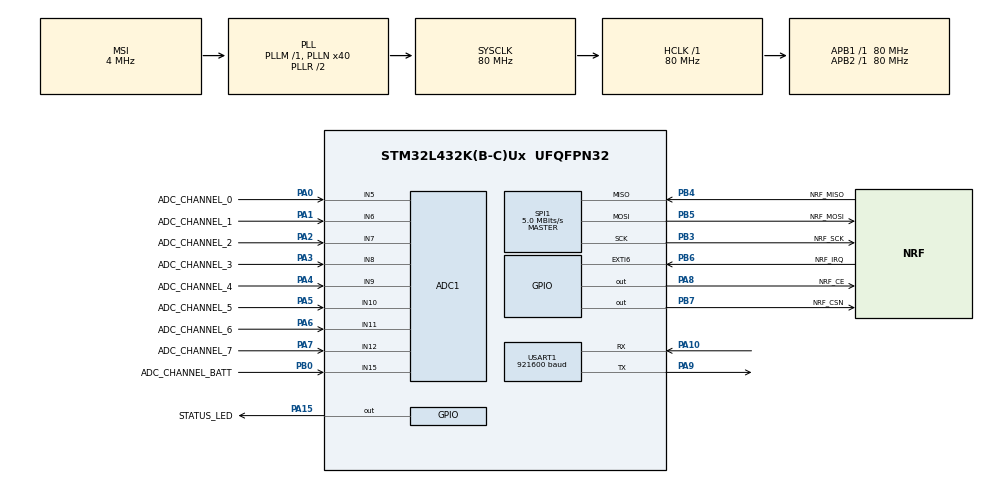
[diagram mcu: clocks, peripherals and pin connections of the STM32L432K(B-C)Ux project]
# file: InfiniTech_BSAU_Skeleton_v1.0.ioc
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ADC1.Channel-0\#ChannelRegularConversion=ADC_CHANNEL_5
ADC1.Channel-1\#ChannelRegularConversion=ADC_CHANNEL_6
ADC1.Channel-2\#ChannelRegularConversion=ADC_CHANNEL_7
ADC1.Channel-3\#ChannelRegularConversion=ADC_CHANNEL_8
ADC1.Channel-4\#ChannelRegularConversion=ADC_CHANNEL_9
ADC1.Channel-5\#ChannelRegularConversion=ADC_CHANNEL_10
ADC1.Channel-6\#ChannelRegularConversion=ADC_CHANNEL_11
ADC1.Channel-7\#ChannelRegularConversion=ADC_CHANNEL_12
ADC1.Channel-8\#ChannelRegularConversion=ADC_CHANNEL_15
ADC1.ClockPrescaler=ADC_CLOCK_SYNC_PCLK_DIV1
ADC1.ContinuousConvMode=DISABLE
ADC1.DMAContinuousRequests=ENABLE
ADC1.ExternalTrigConv=ADC_EXTERNALTRIG_T6_TRGO
ADC1.NbrOfConversion=9
ADC1.NbrOfConversionFlag=1
ADC1.OffsetNumber-0\#ChannelRegularConversion=ADC_OFFSET_NONE
ADC1.OffsetNumber-1\#ChannelRegularConversion=ADC_OFFSET_NONE
ADC1.OffsetNumber-2\#ChannelRegularConversion=ADC_OFFSET_NONE
ADC1.OffsetNumber-3\#ChannelRegularConversion=ADC_OFFSET_NONE
ADC1.OffsetNumber-4\#ChannelRegularConversion=ADC_OFFSET_NONE
ADC1.OffsetNumber-5\#ChannelRegularConversion=ADC_OFFSET_NONE
ADC1.OffsetNumber-6\#ChannelRegularConversion=ADC_OFFSET_NONE
ADC1.OffsetNumber-7\#ChannelRegularConversion=ADC_OFFSET_NONE
ADC1.OffsetNumber-8\#ChannelRegularConversion=ADC_OFFSET_NONE
ADC1.Overrun=ADC_OVR_DATA_OVERWRITTEN
ADC1.OversamplingMode=ENABLE
ADC1.OversamplingStopReset=ADC_REGOVERSAMPLING_CONTINUED_MODE
ADC1.Rank-0\#ChannelRegularConversion=1
ADC1.Rank-1\#ChannelRegularConversion=2
ADC1.Rank-2\#ChannelRegularConversion=3
ADC1.Rank-3\#ChannelRegularConversion=4
ADC1.Rank-4\#ChannelRegularConversion=5
ADC1.Rank-5\#ChannelRegularConversion=6
ADC1.Rank-6\#ChannelRegularConversion=7
ADC1.Rank-7\#ChannelRegularConversion=8
ADC1.Rank-8\#ChannelRegularConversion=9
ADC1.Ratio=ADC_OVERSAMPLING_RATIO_32
ADC1.RightBitShift=ADC_RIGHTBITSHIFT_5
ADC1.SamplingTime-0\#ChannelRegularConversion=ADC_SAMPLETIME_47CYCLES_5
ADC1.SamplingTime-1\#ChannelRegularConversion=ADC_SAMPLETIME_47CYCLES_5
ADC1.SamplingTime-2\#ChannelRegularConversion=ADC_SAMPLETIME_47CYCLES_5
ADC1.SamplingTime-3\#ChannelRegularConversion=ADC_SAMPLETIME_47CYCLES_5
ADC1.SamplingTime-4\#ChannelRegularConversion=ADC_SAMPLETIME_47CYCLES_5
ADC1.SamplingTime-5\#ChannelRegularConversion=ADC_SAMPLETIME_47CYCLES_5
ADC1.SamplingTime-6\#ChannelRegularConversion=ADC_SAMPLETIME_47CYCLES_5
ADC1.SamplingTime-7\#ChannelRegularConversion=ADC_SAMPLETIME_47CYCLES_5
ADC1.SamplingTime-8\#ChannelRegularConversion=ADC_SAMPLETIME_47CYCLES_5
ADC1.TriggeredMode=ADC_TRIGGEREDMODE_SINGLE_TRIGGER
ADC1.master=1
Dma.ADC1.0.Direction=DMA_PERIPH_TO_MEMORY
Dma.ADC1.0.Instance=DMA1_Channel1
Dma.ADC1.0.MemDataAlignment=DMA_MDATAALIGN_HALFWORD
Dma.ADC1.0.MemInc=DMA_MINC_ENABLE
Dma.ADC1.0.Mode=DMA_CIRCULAR
Dma.ADC1.0.PeriphDataAlignment=DMA_PDATAALIGN_HALFWORD
Dma.ADC1.0.PeriphInc=DMA_PINC_DISABLE
Dma.ADC1.0.Priority=DMA_PRIORITY_HIGH
Dma.Request0=ADC1
Mcu.Family=STM32L4
Mcu.Name=STM32L432K(B-C)Ux
Mcu.Package=UFQFPN32
NVIC.DMA1_Channel1_IRQn=true\:1\:0\:true\:false\:true\:false\:true\:true
NVIC.PriorityGroup=NVIC_PRIORITYGROUP_4
PA0.GPIO_Label=ADC_CHANNEL_0
PA0.Signal=ADCx_IN5
PA1.GPIO_Label=ADC_CHANNEL_1
PA1.Signal=ADCx_IN6
PA10.Mode=Asynchronous
PA10.Signal=USART1_RX
PA13\ (JTMS-SWDIO).Mode=Serial_Wire
PA13\ (JTMS-SWDIO).Signal=SYS_JTMS-SWDIO
PA14\ (JTCK-SWCLK).Mode=Serial_Wire
PA14\ (JTCK-SWCLK).Signal=SYS_JTCK-SWCLK
PA15\ (JTDI).GPIO_Label=STATUS_LED
PA15\ (JTDI).Signal=GPIO_Output
PA2.GPIO_Label=ADC_CHANNEL_2
PA2.Signal=ADCx_IN7
PA3.GPIO_Label=ADC_CHANNEL_3
PA3.Signal=ADCx_IN8
PA4.GPIO_Label=ADC_CHANNEL_4
PA4.Signal=ADCx_IN9
PA5.GPIO_Label=ADC_CHANNEL_5
PA5.Signal=ADCx_IN10
PA6.GPIO_Label=ADC_CHANNEL_6
PA6.Signal=ADCx_IN11
PA7.GPIO_Label=ADC_CHANNEL_7
PA7.Signal=ADCx_IN12
PA8.GPIO_Label=NRF_CE
PA8.Signal=GPIO_Output
PA9.Mode=Asynchronous
PA9.Signal=USART1_TX
PB0.GPIO_Label=ADC_CHANNEL_BATT
PB0.Signal=ADCx_IN15
PB3\ (JTDO-TRACESWO).GPIO_Label=NRF_SCK 
PB3\ (JTDO-TRACESWO).Mode=Full_Duplex_Master
PB3\ (JTDO-TRACESWO).Signal=SPI1_SCK
PB4\ (NJTRST).GPIO_Label=NRF_MISO
PB4\ (NJTRST).GPIO_PuPd=GPIO_PULLUP
PB4\ (NJTRST).Mode=Full_Duplex_Master
PB4\ (NJTRST).Signal=SPI1_MISO
PB5.GPIO_Label=NRF_MOSI 
PB5.Mode=Full_Duplex_Master
PB5.Signal=SPI1_MOSI
PB6.GPIO_Label=NRF_IRQ
PB6.GPIO_ModeDefaultEXTI=GPIO_MODE_IT_FALLING
PB6.GPIO_PuPd=GPIO_PULLUP
PB6.Signal=GPXTI6
PB7.GPIO_Label=NRF_CSN
PB7.GPIO_Speed=GPIO_SPEED_FREQ_VERY_HIGH
PB7.PinState=GPIO_PIN_SET
PB7.Signal=GPIO_Output
PC14-OSC32_IN\ (PC14).Mode=LSE-External-Oscillator
PC14-OSC32_IN\ (PC14).Signal=RCC_OSC32_IN
PC15-OSC32_OUT\ (PC15).Mode=LSE-External-Oscillator
PC15-OSC32_OUT\ (PC15).Signal=RCC_OSC32_OUT
ProjectManager.HeapSize=0x200
ProjectManager.StackSize=0x800
ProjectManager.TargetToolchain=STM32CubeIDE
RCC.ADCCLockSelection=RCC_ADCCLKSOURCE_SYSCLK
RCC.ADCFreq_Value=80000000
RCC.AHBFreq_Value=80000000
RCC.APB1Freq_Value=80000000
RCC.APB1TimFreq_Value=80000000
RCC.APB2Freq_Value=80000000
RCC.APB2TimFreq_Value=80000000
RCC.CortexFreq_Value=80000000
RCC.HCLKFreq_Value=80000000
RCC.HSE_VALUE=8000000
RCC.HSI16_VALUE=16000000
RCC.HSI48_VALUE=48000000
RCC.HSI_VALUE=16000000
RCC.LSE_Drive_Capability=RCC_LSEDRIVE_HIGH
RCC.LSE_Drive_CapabilityArg=+LSE_Drive_Capability
RCC.MSIAutoCalibration=ENABLED
RCC.MSI_VALUE=4000000
RCC.PLLMUL=RCC_PLLMUL_4
RCC.PLLN=40
RCC.PLLSAI1N=16
RCC.RTCClockSelection=RCC_RTCCLKSOURCE_LSE
RCC.SYSCLKFreq_VALUE=80000000
RCC.SYSCLKSource=RCC_SYSCLKSOURCE_PLLCLK
RCC.USART1CLockSelection=RCC_USART1CLKSOURCE_SYSCLK
RCC.USBFreq_Value=32000000
RCC.VCOOutputFreq_Value=160000000
SH.ADCx_IN10.0=ADC1_IN10,IN10-Single-Ended
SH.ADCx_IN11.0=ADC1_IN11,IN11-Single-Ended
SH.ADCx_IN12.0=ADC1_IN12,IN12-Single-Ended
SH.ADCx_IN15.0=ADC1_IN15,IN15-Single-Ended
SH.ADCx_IN5.0=ADC1_IN5,IN5-Single-Ended
SH.ADCx_IN6.0=ADC1_IN6,IN6-Single-Ended
SH.ADCx_IN7.0=ADC1_IN7,IN7-Single-Ended
SH.ADCx_IN8.0=ADC1_IN8,IN8-Single-Ended
SH.ADCx_IN9.0=ADC1_IN9,IN9-Single-Ended
SPI1.BaudRatePrescaler=SPI_BAUDRATEPRESCALER_16
SPI1.CalculateBaudRate=5.0 MBits/s
SPI1.DataSize=SPI_DATASIZE_8BIT
SPI1.Direction=SPI_DIRECTION_2LINES
SPI1.Mode=SPI_MODE_MASTER
SPI1.NSSPMode=SPI_NSS_PULSE_DISABLE
SPI1.VirtualType=VM_MASTER
TIM2.Period=0xFFFFFFFF
TIM2.Prescaler=79
TIM6.Period=39999
TIM6.TIM_MasterOutputTrigger=TIM_TRGO_UPDATE
USART1.BaudRate=921600
USART1.VirtualMode-Asynchronous=VM_ASYNC
VP_TIM2_VS_ClockSourceINT.Mode=Internal
VP_TIM6_VS_ClockSourceINT.Mode=Enable_Timer
board=NUCLEO-L432KC

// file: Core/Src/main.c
/**
 *  @file   main.c
 *  @brief  BSAU entry point — HAL init, peripheral setup, application dispatch.
 *
 *  Initializes STM32L432KC clocks, GPIO, SPI, ADC, DMA, TIM6, and USART.
 *  Dispatches to the selected profile (RELEASE/DEBUG/DATASET/TEST) via
 *  BSAU_App_Init() and BSAU_App_Loop().
 */

/**
  ******************************************************************************
  * @file           : main.c
  * @brief          : Main program body
  ******************************************************************************
  * @attention
  *
  * Copyright (c) 2026 STMicroelectronics.
  * All rights reserved.
  *
  * This software is licensed under terms that can be found in the LICENSE file
  * in the root directory of this software component.
  * If no LICENSE file comes with this software, it is provided AS-IS.
  *
  ******************************************************************************
  */
/* USER CODE END Header */
#include "main.h"
#include "adc.h"
#include "dma.h"
#include "spi.h"
#include "tim.h"
#include "usart.h"
#include "gpio.h"

/* USER CODE BEGIN Includes */
#include "bsau_app.h"
/* USER CODE END Includes */

void SystemClock_Config(void);

int main(void)
{

  /* MCU Configuration--------------------------------------------------------*/

  /* Reset of all peripherals, Initializes the Flash interface and the Systick. */
  HAL_Init();

  /* Configure the system clock */
  SystemClock_Config();

  /* USER CODE BEGIN SysInit */

  /*  PA4 is shared with DAC1_OUT1 on the STM32L432KC. After a cold boot
   *  the DAC output buffer may not be fully tri-stated, weakly driving
   *  the pad and injecting a DC offset into the ADC reading. Briefly
   *  enable the DAC clock, force EN1=0 and MODE1=010 (pin connected,
   *  buffer OFF), then kill the clock again. This guarantees the analog
   *  switch is disconnected before the ADC takes ownership of the pin.  */
  __HAL_RCC_DAC1_CLK_ENABLE();
  DAC1->CR   = 0x00000000U;    /* EN1 = 0, all triggers off            */
  DAC1->MCR  = 0x00000002U;    /* MODE1[2:0] = 010: buffer disabled    */
  __HAL_RCC_DAC1_CLK_DISABLE();

  /*  PA3 is shared with OPAMP1_VOUT. OPAMP1 inputs are PA0 (VINP) and
   *  PA1 (VINM) — both EMG channels. If the OPAMP analog switch is not
   *  fully disconnected after reset, it acts as a comparator between ch0
   *  and ch1, overriding the external signal on PA3 with a clipped rail-
   *  to-rail output. Force OPAMPxEN = 0 to disconnect the output path.
   *  Clock is left running — the OPAMP control logic needs it to hold
   *  the analog switch open.                                             */
  __HAL_RCC_OPAMP_CLK_ENABLE();
  OPAMP1->CSR = 0x00000000U;   /* OPAMPxEN = 0, output disconnected    */

  /* USER CODE END SysInit */

  /* Initialize all configured peripherals */
  MX_GPIO_Init();
  MX_DMA_Init();
  MX_ADC1_Init();
  MX_SPI1_Init();
  MX_TIM6_Init();
  MX_USART1_UART_Init();
  MX_TIM2_Init();
  /* USER CODE BEGIN 2 */
  BSAU_Init();
  /* USER CODE END 2 */

  /* Infinite loop */
  while (1)
  {

    /* USER CODE BEGIN 3 */
    BSAU_Run();     /* never returns — contains its own while(1) */
  }
  /* USER CODE END 3 */
}

void SystemClock_Config(void)
{
  RCC_OscInitTypeDef RCC_OscInitStruct = {0};
  RCC_ClkInitTypeDef RCC_ClkInitStruct = {0};

  /** Configure the main internal regulator output voltage
  */
  if (HAL_PWREx_ControlVoltageScaling(PWR_REGULATOR_VOLTAGE_SCALE1) != HAL_OK)
  {
    Error_Handler();
  }

  /** Configure LSE Drive Capability
  */
  HAL_PWR_EnableBkUpAccess();
  __HAL_RCC_LSEDRIVE_CONFIG(RCC_LSEDRIVE_HIGH);

  /** Initializes the RCC Oscillators according to the specified parameters
  * in the RCC_OscInitTypeDef structure.
  */
  RCC_OscInitStruct.OscillatorType = RCC_OSCILLATORTYPE_LSE|RCC_OSCILLATORTYPE_MSI;
  RCC_OscInitStruct.LSEState = RCC_LSE_ON;
  RCC_OscInitStruct.MSIState = RCC_MSI_ON;
  RCC_OscInitStruct.MSICalibrationValue = 0;
  RCC_OscInitStruct.MSIClockRange = RCC_MSIRANGE_6;
  RCC_OscInitStruct.PLL.PLLState = RCC_PLL_ON;
  RCC_OscInitStruct.PLL.PLLSource = RCC_PLLSOURCE_MSI;
  RCC_OscInitStruct.PLL.PLLM = 1;
  RCC_OscInitStruct.PLL.PLLN = 40;
  RCC_OscInitStruct.PLL.PLLP = RCC_PLLP_DIV7;
  RCC_OscInitStruct.PLL.PLLQ = RCC_PLLQ_DIV2;
  RCC_OscInitStruct.PLL.PLLR = RCC_PLLR_DIV2;
  if (HAL_RCC_OscConfig(&RCC_OscInitStruct) != HAL_OK)
  {
    Error_Handler();
  }

  /** Initializes the CPU, AHB and APB buses clocks
  */
  RCC_ClkInitStruct.ClockType = RCC_CLOCKTYPE_HCLK|RCC_CLOCKTYPE_SYSCLK
                              |RCC_CLOCKTYPE_PCLK1|RCC_CLOCKTYPE_PCLK2;
  RCC_ClkInitStruct.SYSCLKSource = RCC_SYSCLKSOURCE_PLLCLK;
  RCC_ClkInitStruct.AHBCLKDivider = RCC_SYSCLK_DIV1;
  RCC_ClkInitStruct.APB1CLKDivider = RCC_HCLK_DIV1;
  RCC_ClkInitStruct.APB2CLKDivider = RCC_HCLK_DIV1;

  if (HAL_RCC_ClockConfig(&RCC_ClkInitStruct, FLASH_LATENCY_4) != HAL_OK)
  {
    Error_Handler();
  }

  /** Enable MSI Auto calibration
  */
  HAL_RCCEx_EnableMSIPLLMode();
}

void Error_Handler(void)
{
  __disable_irq();
  while (1)
  {
  }
}
